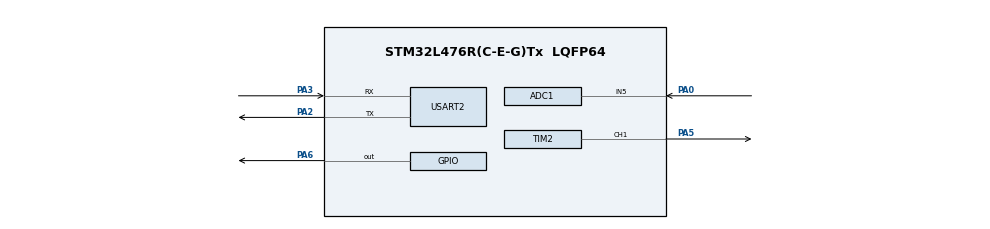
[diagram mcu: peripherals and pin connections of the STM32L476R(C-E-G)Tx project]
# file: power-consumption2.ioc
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ADC1.Channel-0\#ChannelRegularConversion=ADC_CHANNEL_5
ADC1.NbrOfConversionFlag=1
ADC1.OffsetNumber-0\#ChannelRegularConversion=ADC_OFFSET_NONE
ADC1.Rank-0\#ChannelRegularConversion=1
ADC1.SamplingTime-0\#ChannelRegularConversion=ADC_SAMPLETIME_2CYCLES_5
ADC1.master=1
FREERTOS.Tasks01=defaultTask,0,128,StartDefaultTask,Default,NULL,Dynamic,NULL,NULL
Mcu.Family=STM32L4
Mcu.Name=STM32L476R(C-E-G)Tx
Mcu.Package=LQFP64
NVIC.PriorityGroup=NVIC_PRIORITYGROUP_4
NVIC.TIM1_UP_TIM16_IRQn=true\:15\:0\:false\:false\:true\:false\:false\:true
NVIC.TIM3_IRQn=true\:5\:0\:false\:false\:true\:true\:true\:true
NVIC.TimeBase=TIM1_UP_TIM16_IRQn
NVIC.TimeBaseIP=TIM1
NVIC.USART2_IRQn=true\:5\:0\:false\:false\:true\:true\:true\:true
PA0.Signal=ADCx_IN5
PA13\ (JTMS-SWDIO).Mode=Serial_Wire
PA13\ (JTMS-SWDIO).Signal=SYS_JTMS-SWDIO
PA14\ (JTCK-SWCLK).Mode=Serial_Wire
PA14\ (JTCK-SWCLK).Signal=SYS_JTCK-SWCLK
PA2.Mode=Asynchronous
PA2.Signal=USART2_TX
PA3.Mode=Asynchronous
PA3.Signal=USART2_RX
PA5.Signal=S_TIM2_CH1
PA6.Signal=GPIO_Output
ProjectManager.HeapSize=0x200
ProjectManager.StackSize=0x400
ProjectManager.TargetToolchain=STM32CubeIDE
RCC.ADCFreq_Value=32000000
RCC.HSE_VALUE=8000000
RCC.HSI_VALUE=16000000
RCC.LSE_VALUE=32768
RCC.MSI_VALUE=4000000
RCC.PLLSAI1N=16
RCC.USBFreq_Value=32000000
RCC.VCOOutputFreq_Value=32000000
SH.ADCx_IN5.0=ADC1_IN5,IN5-Single-Ended
SH.S_TIM2_CH1.0=TIM2_CH1,PWM Generation1 CH1
TIM2.Channel-PWM\ Generation1\ CH1=TIM_CHANNEL_1
TIM2.Period=2000-1
TIM2.Prescaler=127
TIM3.Period=10000-1
TIM3.Prescaler=400-1
USART2.VirtualMode-Asynchronous=VM_ASYNC
VP_FREERTOS_VS_CMSIS_V1.Mode=CMSIS_V1
VP_SYS_VS_tim1.Mode=TIM1
VP_TIM2_VS_ClockSourceINT.Mode=Internal
VP_TIM3_VS_ClockSourceINT.Mode=Internal
board=custom

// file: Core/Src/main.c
/* USER CODE BEGIN Header */
/**
  ******************************************************************************
  * @file           : main.c
  * @brief          : Main program body
  ******************************************************************************
  * @attention
  *
  * <h2><center>&copy; Copyright (c) 2021 STMicroelectronics.
  * All rights reserved.</center></h2>
  *
  * This software component is licensed by ST under Ultimate Liberty license
  * SLA0044, the "License"; You may not use this file except in compliance with
  * the License. You may obtain a copy of the License at:
  *                             www.st.com/SLA0044
  *
  ******************************************************************************
  */
/* USER CODE END Header */
#include "main.h"
#include "cmsis_os.h"

/* USER CODE BEGIN Includes */
#include <stdio.h>
/* USER CODE END Includes */

ADC_HandleTypeDef hadc1;

TIM_HandleTypeDef htim2;
TIM_HandleTypeDef htim3;

osThreadId defaultTaskHandle;

void SystemClock_Config(void);
static void MX_GPIO_Init(void);
static void MX_ADC1_Init(void);
static void MX_TIM2_Init(void);
static void MX_TIM3_Init(void);
static void MX_USART2_UART_Init(void);
void StartDefaultTask(void const * argument);

/* USER CODE BEGIN 0 */

void root_task(void * args) {
	for(;;) {
		printf("Hello");
	}
}

/* USER CODE END 0 */

int main(void)
{

  /* MCU Configuration--------------------------------------------------------*/

  /* Reset of all peripherals, Initializes the Flash interface and the Systick. */
  HAL_Init();

  /* Configure the system clock */
  SystemClock_Config();

  /* Initialize all configured peripherals */
  MX_GPIO_Init();
  MX_ADC1_Init();
  MX_TIM2_Init();
  MX_TIM3_Init();
  MX_USART2_UART_Init();

  /* Create the thread(s) */
  /* definition and creation of defaultTask */
  osThreadDef(defaultTask, StartDefaultTask, osPriorityNormal, 0, 128);
  defaultTaskHandle = osThreadCreate(osThread(defaultTask), NULL);

  /* USER CODE BEGIN RTOS_THREADS */
  /* add threads, ... */

  xTaskCreate(root_task, "@root", configMINIMAL_STACK_SIZE, NULL, tskIDLE_PRIORITY, NULL);

  /* USER CODE END RTOS_THREADS */

  /* Start scheduler */
  osKernelStart();

  /* We should never get here as control is now taken by the scheduler */
  /* Infinite loop */
  while (1)
  {

  }
}

void SystemClock_Config(void)
{
  RCC_OscInitTypeDef RCC_OscInitStruct = {0};
  RCC_ClkInitTypeDef RCC_ClkInitStruct = {0};

  /** Configure the main internal regulator output voltage
  */
  if (HAL_PWREx_ControlVoltageScaling(PWR_REGULATOR_VOLTAGE_SCALE1) != HAL_OK)
  {
    Error_Handler();
  }
  /** Initializes the RCC Oscillators according to the specified parameters
  * in the RCC_OscInitTypeDef structure.
  */
  RCC_OscInitStruct.OscillatorType = RCC_OSCILLATORTYPE_MSI;
  RCC_OscInitStruct.MSIState = RCC_MSI_ON;
  RCC_OscInitStruct.MSICalibrationValue = 0;
  RCC_OscInitStruct.MSIClockRange = RCC_MSIRANGE_6;
  RCC_OscInitStruct.PLL.PLLState = RCC_PLL_NONE;
  if (HAL_RCC_OscConfig(&RCC_OscInitStruct) != HAL_OK)
  {
    Error_Handler();
  }
  /** Initializes the CPU, AHB and APB buses clocks
  */
  RCC_ClkInitStruct.ClockType = RCC_CLOCKTYPE_HCLK|RCC_CLOCKTYPE_SYSCLK
                              |RCC_CLOCKTYPE_PCLK1|RCC_CLOCKTYPE_PCLK2;
  RCC_ClkInitStruct.SYSCLKSource = RCC_SYSCLKSOURCE_MSI;
  RCC_ClkInitStruct.AHBCLKDivider = RCC_SYSCLK_DIV1;
  RCC_ClkInitStruct.APB1CLKDivider = RCC_HCLK_DIV1;
  RCC_ClkInitStruct.APB2CLKDivider = RCC_HCLK_DIV1;

  if (HAL_RCC_ClockConfig(&RCC_ClkInitStruct, FLASH_LATENCY_0) != HAL_OK)
  {
    Error_Handler();
  }
}

static void MX_ADC1_Init(void)
{

  ADC_MultiModeTypeDef multimode = {0};
  ADC_ChannelConfTypeDef sConfig = {0};

  /** Common config
  */
  hadc1.Instance = ADC1;
  hadc1.Init.ClockPrescaler = ADC_CLOCK_ASYNC_DIV1;
  hadc1.Init.Resolution = ADC_RESOLUTION_12B;
  hadc1.Init.DataAlign = ADC_DATAALIGN_RIGHT;
  hadc1.Init.ScanConvMode = ADC_SCAN_DISABLE;
  hadc1.Init.EOCSelection = ADC_EOC_SINGLE_CONV;
  hadc1.Init.LowPowerAutoWait = DISABLE;
  hadc1.Init.ContinuousConvMode = DISABLE;
  hadc1.Init.NbrOfConversion = 1;
  hadc1.Init.DiscontinuousConvMode = DISABLE;
  hadc1.Init.ExternalTrigConv = ADC_SOFTWARE_START;
  hadc1.Init.ExternalTrigConvEdge = ADC_EXTERNALTRIGCONVEDGE_NONE;
  hadc1.Init.DMAContinuousRequests = DISABLE;
  hadc1.Init.Overrun = ADC_OVR_DATA_PRESERVED;
  hadc1.Init.OversamplingMode = DISABLE;
  if (HAL_ADC_Init(&hadc1) != HAL_OK)
  {
    Error_Handler();
  }
  /** Configure the ADC multi-mode
  */
  multimode.Mode = ADC_MODE_INDEPENDENT;
  if (HAL_ADCEx_MultiModeConfigChannel(&hadc1, &multimode) != HAL_OK)
  {
    Error_Handler();
  }
  /** Configure Regular Channel
  */
  sConfig.Channel = ADC_CHANNEL_5;
  sConfig.Rank = ADC_REGULAR_RANK_1;
  sConfig.SamplingTime = ADC_SAMPLETIME_2CYCLES_5;
  sConfig.SingleDiff = ADC_SINGLE_ENDED;
  sConfig.OffsetNumber = ADC_OFFSET_NONE;
  sConfig.Offset = 0;
  if (HAL_ADC_ConfigChannel(&hadc1, &sConfig) != HAL_OK)
  {
    Error_Handler();
  }

}

static void MX_TIM2_Init(void)
{

  TIM_ClockConfigTypeDef sClockSourceConfig = {0};
  TIM_MasterConfigTypeDef sMasterConfig = {0};
  TIM_OC_InitTypeDef sConfigOC = {0};

  htim2.Instance = TIM2;
  htim2.Init.Prescaler = 127;
  htim2.Init.CounterMode = TIM_COUNTERMODE_UP;
  htim2.Init.Period = 2000-1;
  htim2.Init.ClockDivision = TIM_CLOCKDIVISION_DIV1;
  htim2.Init.AutoReloadPreload = TIM_AUTORELOAD_PRELOAD_DISABLE;
  if (HAL_TIM_Base_Init(&htim2) != HAL_OK)
  {
    Error_Handler();
  }
  sClockSourceConfig.ClockSource = TIM_CLOCKSOURCE_INTERNAL;
  if (HAL_TIM_ConfigClockSource(&htim2, &sClockSourceConfig) != HAL_OK)
  {
    Error_Handler();
  }
  if (HAL_TIM_PWM_Init(&htim2) != HAL_OK)
  {
    Error_Handler();
  }
  sMasterConfig.MasterOutputTrigger = TIM_TRGO_RESET;
  sMasterConfig.MasterSlaveMode = TIM_MASTERSLAVEMODE_DISABLE;
  if (HAL_TIMEx_MasterConfigSynchronization(&htim2, &sMasterConfig) != HAL_OK)
  {
    Error_Handler();
  }
  sConfigOC.OCMode = TIM_OCMODE_PWM1;
  sConfigOC.Pulse = 0;
  sConfigOC.OCPolarity = TIM_OCPOLARITY_HIGH;
  sConfigOC.OCFastMode = TIM_OCFAST_DISABLE;
  if (HAL_TIM_PWM_ConfigChannel(&htim2, &sConfigOC, TIM_CHANNEL_1) != HAL_OK)
  {
    Error_Handler();
  }
  HAL_TIM_MspPostInit(&htim2);

}

static void MX_TIM3_Init(void)
{

  TIM_ClockConfigTypeDef sClockSourceConfig = {0};
  TIM_MasterConfigTypeDef sMasterConfig = {0};

  htim3.Instance = TIM3;
  htim3.Init.Prescaler = 400-1;
  htim3.Init.CounterMode = TIM_COUNTERMODE_UP;
  htim3.Init.Period = 10000-1;
  htim3.Init.ClockDivision = TIM_CLOCKDIVISION_DIV1;
  htim3.Init.AutoReloadPreload = TIM_AUTORELOAD_PRELOAD_DISABLE;
  if (HAL_TIM_Base_Init(&htim3) != HAL_OK)
  {
    Error_Handler();
  }
  sClockSourceConfig.ClockSource = TIM_CLOCKSOURCE_INTERNAL;
  if (HAL_TIM_ConfigClockSource(&htim3, &sClockSourceConfig) != HAL_OK)
  {
    Error_Handler();
  }
  sMasterConfig.MasterOutputTrigger = TIM_TRGO_RESET;
  sMasterConfig.MasterSlaveMode = TIM_MASTERSLAVEMODE_DISABLE;
  if (HAL_TIMEx_MasterConfigSynchronization(&htim3, &sMasterConfig) != HAL_OK)
  {
    Error_Handler();
  }

}

static void MX_USART2_UART_Init(void)
{

  LL_USART_InitTypeDef USART_InitStruct = {0};

  LL_GPIO_InitTypeDef GPIO_InitStruct = {0};
  RCC_PeriphCLKInitTypeDef PeriphClkInit = {0};

  /** Initializes the peripherals clock
  */
  PeriphClkInit.PeriphClockSelection = RCC_PERIPHCLK_USART2;
  PeriphClkInit.Usart2ClockSelection = RCC_USART2CLKSOURCE_PCLK1;
  if (HAL_RCCEx_PeriphCLKConfig(&PeriphClkInit) != HAL_OK)
  {
    Error_Handler();
  }

  /* Peripheral clock enable */
  LL_APB1_GRP1_EnableClock(LL_APB1_GRP1_PERIPH_USART2);

  LL_AHB2_GRP1_EnableClock(LL_AHB2_GRP1_PERIPH_GPIOA);
  /**USART2 GPIO Configuration
  PA2   ------> USART2_TX
  PA3   ------> USART2_RX
  */
  GPIO_InitStruct.Pin = LL_GPIO_PIN_2|LL_GPIO_PIN_3;
  GPIO_InitStruct.Mode = LL_GPIO_MODE_ALTERNATE;
  GPIO_InitStruct.Speed = LL_GPIO_SPEED_FREQ_VERY_HIGH;
  GPIO_InitStruct.OutputType = LL_GPIO_OUTPUT_PUSHPULL;
  GPIO_InitStruct.Pull = LL_GPIO_PULL_NO;
  GPIO_InitStruct.Alternate = LL_GPIO_AF_7;
  LL_GPIO_Init(GPIOA, &GPIO_InitStruct);

  /* USART2 interrupt Init */
  NVIC_SetPriority(USART2_IRQn, NVIC_EncodePriority(NVIC_GetPriorityGrouping(),5, 0));
  NVIC_EnableIRQ(USART2_IRQn);

  USART_InitStruct.BaudRate = 115200;
  USART_InitStruct.DataWidth = LL_USART_DATAWIDTH_8B;
  USART_InitStruct.StopBits = LL_USART_STOPBITS_1;
  USART_InitStruct.Parity = LL_USART_PARITY_NONE;
  USART_InitStruct.TransferDirection = LL_USART_DIRECTION_TX_RX;
  USART_InitStruct.HardwareFlowControl = LL_USART_HWCONTROL_NONE;
  USART_InitStruct.OverSampling = LL_USART_OVERSAMPLING_16;
  LL_USART_Init(USART2, &USART_InitStruct);
  LL_USART_ConfigAsyncMode(USART2);
  LL_USART_Enable(USART2);

}

static void MX_GPIO_Init(void)
{
  GPIO_InitTypeDef GPIO_InitStruct = {0};

  /* GPIO Ports Clock Enable */
  __HAL_RCC_GPIOA_CLK_ENABLE();

  /*Configure GPIO pin Output Level */
  HAL_GPIO_WritePin(GPIOA, GPIO_PIN_6, GPIO_PIN_RESET);

  /*Configure GPIO pin : PA6 */
  GPIO_InitStruct.Pin = GPIO_PIN_6;
  GPIO_InitStruct.Mode = GPIO_MODE_OUTPUT_PP;
  GPIO_InitStruct.Pull = GPIO_NOPULL;
  GPIO_InitStruct.Speed = GPIO_SPEED_FREQ_LOW;
  HAL_GPIO_Init(GPIOA, &GPIO_InitStruct);

}

void StartDefaultTask(void const * argument)
{
  for(;;)
  {
    osDelay(1);
  }
}

void HAL_TIM_PeriodElapsedCallback(TIM_HandleTypeDef *htim)
{
  if (htim->Instance == TIM1) {
    HAL_IncTick();
  }
}

void Error_Handler(void)
{
  __disable_irq();
  while (1)
  {
  }
}

/************************ (C) COPYRIGHT STMicroelectronics *****END OF FILE****/
